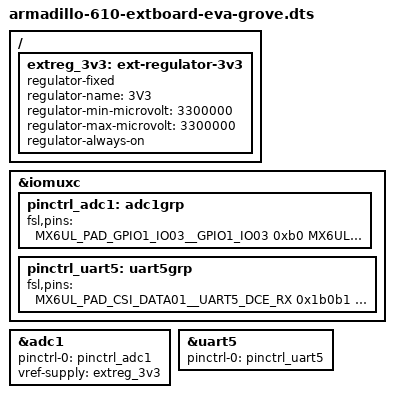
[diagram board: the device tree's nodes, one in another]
/*
 * Copyright (C) 2020 Atmark Techno, Inc. All Rights Reserved.
 *
 * SPDX-License-Identifier: (GPL-2.0 OR MIT)
 */

#define ARMADILLO610_EXTBOARD_EVA
#include "armadillo-610.dtsi"
#include "armadillo-610-extboard-eva-common.dtsi"

/ {
	extreg_3v3: ext-regulator-3v3 {
		compatible = "regulator-fixed";
		regulator-name = "3V3";
		regulator-min-microvolt = <3300000>;
		regulator-max-microvolt = <3300000>;
		regulator-always-on;
	};
};

&iomuxc {
	pinctrl_adc1: adc1grp {
		fsl,pins = <
			MX6UL_PAD_GPIO1_IO03__GPIO1_IO03 0xb0 // CON9_1
			MX6UL_PAD_GPIO1_IO02__GPIO1_IO02 0xb0 // CON9_2
			MX6UL_PAD_GPIO1_IO04__GPIO1_IO04 0xb0 // CON10_1
			MX6UL_PAD_GPIO1_IO01__GPIO1_IO01 0xb0 // CON10_2
		>;
	};

	pinctrl_uart5: uart5grp {
		fsl,pins = <
			MX6UL_PAD_CSI_DATA01__UART5_DCE_RX 0x1b0b1 // CON7_1
			MX6UL_PAD_CSI_DATA00__UART5_DCE_TX 0x00008 // CON7_2
		>;
	};
};

&adc1 {
	pinctrl-names = "default";
	pinctrl-0 = <&pinctrl_adc1>;
	vref-supply = <&extreg_3v3>;
	status = "okay";
};

&uart5 {
	pinctrl-names = "default";
	pinctrl-0 = <&pinctrl_uart5>;
	status = "okay";
};
